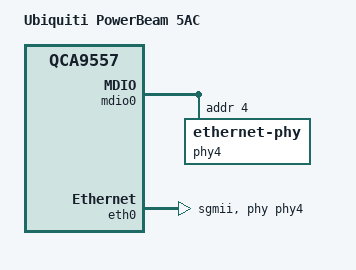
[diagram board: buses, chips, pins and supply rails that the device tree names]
// SPDX-License-Identifier: GPL-2.0
/dts-v1/;

#include "qca9557_ubnt_xc.dtsi"

/ {
	compatible = "ubnt,powerbeam-5ac", "ubnt,xc", "qca,qca9557";
	model = "Ubiquiti PowerBeam 5AC";

	chosen {
		bootargs = "console=ttyS0,115200n8";
	};
};

&mdio0 {
	status = "okay";

	phy-mask = <4>;
	phy4: ethernet-phy@4 {
		phy-mode = "sgmii";
		reg = <4>;
	};
};

&eth0 {
	status = "okay";

	mtd-mac-address = <&art 0x0>;
	phy-mode = "sgmii";
	phy-handle = <&phy4>;
};
